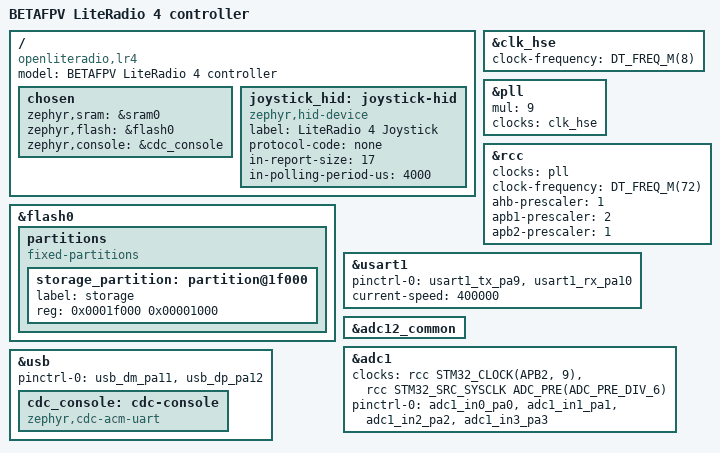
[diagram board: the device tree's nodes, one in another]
/dts-v1/;
#include <st/f1/stm32f103Xb.dtsi>
#include <st/f1/stm32f103r(8-b)tx-pinctrl.dtsi>

/ {
    model = "BETAFPV LiteRadio 4 controller";
    compatible = "openliteradio,lr4";
    chosen {
        zephyr,sram = &sram0;
        zephyr,flash = &flash0;
        zephyr,console = &cdc_console;
    };

    /* USB joystick: channels 1 to 8 as axes, 9 to 16 as buttons; see src/core/joystick.h. */
    joystick_hid: joystick-hid {
        compatible = "zephyr,hid-device";
        label = "LiteRadio 4 Joystick";
        protocol-code = "none";
        in-report-size = <17>;
        in-polling-period-us = <4000>;
    };
};

/* 8 MHz crystal, PLL x9, 72 MHz: the configuration the vendor bootloader uses. */
&clk_hse {
    clock-frequency = <DT_FREQ_M(8)>;
    status = "okay";
};

&pll {
    mul = <9>;
    clocks = <&clk_hse>;
    status = "okay";
};

&rcc {
    clocks = <&pll>;
    clock-frequency = <DT_FREQ_M(72)>;
    ahb-prescaler = <1>;
    apb1-prescaler = <2>;
    apb2-prescaler = <1>;
};

/*
 * The last four 1 KiB pages hold the settings. The image ends below them
 * (CONFIG_FLASH_LOAD_SIZE in prj.conf).
 */
&flash0 {
    partitions {
        compatible = "fixed-partitions";
        #address-cells = <1>;
        #size-cells = <1>;

        storage_partition: partition@1f000 {
            label = "storage";
            reg = <0x0001f000 0x00001000>;
        };
    };
};

&usart1 {
    pinctrl-0 = <&usart1_tx_pa9 &usart1_rx_pa10>;
    pinctrl-names = "default";
    current-speed = <400000>;
    status = "okay";
};

/* Common block of ADC1 and ADC2; must be enabled for adc1 to work. */
&adc12_common {
    status = "okay";
};

&adc1 {
    /*
     * ADC prescaler 6: PCLK2 / 6 = 12 MHz, below the 14 MHz ADC limit.
     * The F1 bindings have no PCLK2 source id; SYSCLK equals PCLK2 here.
     */
    clocks = <&rcc STM32_CLOCK(APB2, 9)>,
             <&rcc STM32_SRC_SYSCLK ADC_PRE(ADC_PRE_DIV_6)>;
    clock-names = "adcx", "adc_pre";
    pinctrl-0 = <&adc1_in0_pa0 &adc1_in1_pa1 &adc1_in2_pa2 &adc1_in3_pa3>;
    pinctrl-names = "default";
    status = "okay";
};

/* USB device: a serial port for the console and the host protocol, and the joystick. */
zephyr_udc0: &usb {
    pinctrl-0 = <&usb_dm_pa11 &usb_dp_pa12>;
    pinctrl-names = "default";
    status = "okay";
    cdc_console: cdc-console {
        compatible = "zephyr,cdc-acm-uart";
    };
};
